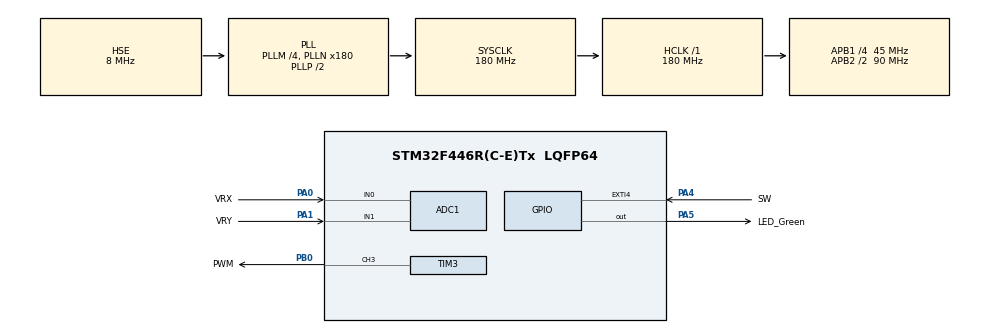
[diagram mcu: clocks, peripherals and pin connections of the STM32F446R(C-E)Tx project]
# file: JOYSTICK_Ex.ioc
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ADC1.Channel-2\#ChannelRegularConversion=ADC_CHANNEL_0
ADC1.Channel-3\#ChannelRegularConversion=ADC_CHANNEL_1
ADC1.ContinuousConvMode=ENABLE
ADC1.DMAContinuousRequests=ENABLE
ADC1.NbrOfConversion=2
ADC1.NbrOfConversionFlag=1
ADC1.Rank-2\#ChannelRegularConversion=1
ADC1.Rank-3\#ChannelRegularConversion=2
ADC1.SamplingTime-2\#ChannelRegularConversion=ADC_SAMPLETIME_84CYCLES
ADC1.SamplingTime-3\#ChannelRegularConversion=ADC_SAMPLETIME_84CYCLES
ADC1.master=1
Dma.ADC1.0.Direction=DMA_PERIPH_TO_MEMORY
Dma.ADC1.0.FIFOMode=DMA_FIFOMODE_DISABLE
Dma.ADC1.0.Instance=DMA2_Stream0
Dma.ADC1.0.MemDataAlignment=DMA_MDATAALIGN_HALFWORD
Dma.ADC1.0.MemInc=DMA_MINC_ENABLE
Dma.ADC1.0.Mode=DMA_CIRCULAR
Dma.ADC1.0.PeriphDataAlignment=DMA_PDATAALIGN_HALFWORD
Dma.ADC1.0.PeriphInc=DMA_PINC_DISABLE
Dma.ADC1.0.Priority=DMA_PRIORITY_LOW
Dma.Request0=ADC1
Mcu.Family=STM32F4
Mcu.Name=STM32F446R(C-E)Tx
Mcu.Package=LQFP64
NVIC.DMA2_Stream0_IRQn=true\:0\:0\:false\:false\:true\:false\:true
NVIC.EXTI4_IRQn=true\:0\:0\:false\:false\:true\:true\:true
NVIC.PriorityGroup=NVIC_PRIORITYGROUP_4
NVIC.TIM3_IRQn=true\:0\:0\:false\:false\:true\:true\:true
PA0-WKUP.GPIO_Label=VRX
PA0-WKUP.Signal=ADCx_IN0
PA1.GPIO_Label=VRY
PA1.Signal=ADCx_IN1
PA4.GPIO_Label=SW
PA4.GPIO_ModeDefaultEXTI=GPIO_MODE_IT_RISING
PA4.GPIO_PuPd=GPIO_PULLDOWN
PA4.Signal=GPXTI4
PA5.GPIO_Label=LED_Green
PA5.Signal=GPIO_Output
PB0.GPIO_Label=PWM
PB0.Signal=S_TIM3_CH3
PH0-OSC_IN.Mode=HSE-External-Oscillator
PH0-OSC_IN.Signal=RCC_OSC_IN
PH1-OSC_OUT.Mode=HSE-External-Oscillator
PH1-OSC_OUT.Signal=RCC_OSC_OUT
ProjectManager.HeapSize=0x200
ProjectManager.StackSize=0x400
ProjectManager.TargetToolchain=STM32CubeIDE
RCC.AHBFreq_Value=180000000
RCC.APB1CLKDivider=RCC_HCLK_DIV4
RCC.APB1Freq_Value=45000000
RCC.APB1TimFreq_Value=90000000
RCC.APB2CLKDivider=RCC_HCLK_DIV2
RCC.APB2Freq_Value=90000000
RCC.APB2TimFreq_Value=180000000
RCC.CortexFreq_Value=180000000
RCC.HCLKFreq_Value=180000000
RCC.HSE_VALUE=8000000
RCC.PLLM=4
RCC.PLLN=180
RCC.PLLSourceVirtual=RCC_PLLSOURCE_HSE
RCC.SYSCLKFreq_VALUE=180000000
RCC.SYSCLKSource=RCC_SYSCLKSOURCE_PLLCLK
RCC.USBFreq_Value=180000000
RCC.VCOOutputFreq_Value=360000000
SH.ADCx_IN0.0=ADC1_IN0,IN0
SH.ADCx_IN1.0=ADC1_IN1,IN1
SH.S_TIM3_CH3.0=TIM3_CH3,PWM Generation3 CH3
TIM3.Channel-PWM\ Generation3\ CH3=TIM_CHANNEL_3
TIM3.Period=10000-1
TIM3.Prescaler=180-1
VP_TIM3_VS_ClockSourceINT.Mode=Internal
board=custom

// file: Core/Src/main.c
/* USER CODE BEGIN Header */
/**
  ******************************************************************************
  * @file           : main.c
  * @brief          : Main program body
  ******************************************************************************
  * @attention
  *
  * <h2><center>&copy; Copyright (c) 2020 STMicroelectronics.
  * All rights reserved.</center></h2>
  *
  * This software component is licensed by ST under BSD 3-Clause license,
  * the "License"; You may not use this file except in compliance with the
  * License. You may obtain a copy of the License at:
  *                        opensource.org/licenses/BSD-3-Clause
  *
  ******************************************************************************
  */
/* USER CODE END Header */

#include "main.h"

ADC_HandleTypeDef hadc1;
DMA_HandleTypeDef hdma_adc1;

TIM_HandleTypeDef htim3;

/* USER CODE BEGIN PV */
uint16_t Joystick_Data[2];
uint32_t Pwm=0;
uint16_t i=450;

/* USER CODE END PV */

void SystemClock_Config(void);
static void MX_GPIO_Init(void);
static void MX_DMA_Init(void);
static void MX_ADC1_Init(void);
static void MX_TIM3_Init(void);

/* USER CODE BEGIN 0 */
uint32_t map(uint32_t data ,uint32_t bound_0,uint32_t bound_1,uint32_t new_bound_0,uint32_t new_bound_1){

	return ((data-bound_0)*(new_bound_1-new_bound_0))/(bound_1-bound_0)+new_bound_0;
}
void HAL_GPIO_EXTI_Callback(uint16_t GPIO_Pin) {
	/*if(EXTI->PR & 1<<4)
	 HAL_GPIO_TogglePin(GPIOA, GPIO_PIN_5);
	 EXTI->PR	|= 1<<4;		//	Clear interrupt flag*/

}

void HAL_ADC_ConvCpltCallback(ADC_HandleTypeDef *hadc) {
	Pwm = map(Joystick_Data[0], 0, 4095, 450, 1310);
}

/* USER CODE END 0 */

int main(void)
{

  /* MCU Configuration--------------------------------------------------------*/

  /* Reset of all peripherals, Initializes the Flash interface and the Systick. */
  HAL_Init();

  /* Configure the system clock */
  SystemClock_Config();

  /* Initialize all configured peripherals */
  MX_GPIO_Init();
  MX_DMA_Init();
  MX_ADC1_Init();
  MX_TIM3_Init();
  /* USER CODE BEGIN 2 */
  HAL_ADC_Start_DMA(&hadc1,(uint32_t*)Joystick_Data,2);
  HAL_TIM_PWM_Start(&htim3, TIM_CHANNEL_3);
  /* USER CODE END 2 */

  /* Infinite loop */
  /* USER CODE BEGIN WHILE */
	while (1) {
		__HAL_TIM_SET_COMPARE(&htim3, TIM_CHANNEL_3, Pwm);
		HAL_Delay(1);

		/*while(i<1310){
			__HAL_TIM_SET_COMPARE(&htim3, TIM_CHANNEL_3, i);
			HAL_Delay(1);
			i++;
		}
		while(i>450){
			__HAL_TIM_SET_COMPARE(&htim3, TIM_CHANNEL_3, i);
						HAL_Delay(1);
						i--;
		}*/

		/* USER CODE END WHILE */

  }
}

void SystemClock_Config(void)
{
  RCC_OscInitTypeDef RCC_OscInitStruct = {0};
  RCC_ClkInitTypeDef RCC_ClkInitStruct = {0};

  /** Configure the main internal regulator output voltage
  */
  __HAL_RCC_PWR_CLK_ENABLE();
  __HAL_PWR_VOLTAGESCALING_CONFIG(PWR_REGULATOR_VOLTAGE_SCALE1);
  /** Initializes the CPU, AHB and APB busses clocks
  */
  RCC_OscInitStruct.OscillatorType = RCC_OSCILLATORTYPE_HSE;
  RCC_OscInitStruct.HSEState = RCC_HSE_ON;
  RCC_OscInitStruct.PLL.PLLState = RCC_PLL_ON;
  RCC_OscInitStruct.PLL.PLLSource = RCC_PLLSOURCE_HSE;
  RCC_OscInitStruct.PLL.PLLM = 4;
  RCC_OscInitStruct.PLL.PLLN = 180;
  RCC_OscInitStruct.PLL.PLLP = RCC_PLLP_DIV2;
  RCC_OscInitStruct.PLL.PLLQ = 2;
  RCC_OscInitStruct.PLL.PLLR = 2;
  if (HAL_RCC_OscConfig(&RCC_OscInitStruct) != HAL_OK)
  {
    Error_Handler();
  }
  /** Activate the Over-Drive mode
  */
  if (HAL_PWREx_EnableOverDrive() != HAL_OK)
  {
    Error_Handler();
  }
  /** Initializes the CPU, AHB and APB busses clocks
  */
  RCC_ClkInitStruct.ClockType = RCC_CLOCKTYPE_HCLK|RCC_CLOCKTYPE_SYSCLK
                              |RCC_CLOCKTYPE_PCLK1|RCC_CLOCKTYPE_PCLK2;
  RCC_ClkInitStruct.SYSCLKSource = RCC_SYSCLKSOURCE_PLLCLK;
  RCC_ClkInitStruct.AHBCLKDivider = RCC_SYSCLK_DIV1;
  RCC_ClkInitStruct.APB1CLKDivider = RCC_HCLK_DIV4;
  RCC_ClkInitStruct.APB2CLKDivider = RCC_HCLK_DIV2;

  if (HAL_RCC_ClockConfig(&RCC_ClkInitStruct, FLASH_LATENCY_5) != HAL_OK)
  {
    Error_Handler();
  }
}

static void MX_ADC1_Init(void)
{

  ADC_ChannelConfTypeDef sConfig = {0};

  /** Configure the global features of the ADC (Clock, Resolution, Data Alignment and number of conversion)
  */
  hadc1.Instance = ADC1;
  hadc1.Init.ClockPrescaler = ADC_CLOCK_SYNC_PCLK_DIV4;
  hadc1.Init.Resolution = ADC_RESOLUTION_12B;
  hadc1.Init.ScanConvMode = ENABLE;
  hadc1.Init.ContinuousConvMode = ENABLE;
  hadc1.Init.DiscontinuousConvMode = DISABLE;
  hadc1.Init.ExternalTrigConvEdge = ADC_EXTERNALTRIGCONVEDGE_NONE;
  hadc1.Init.ExternalTrigConv = ADC_SOFTWARE_START;
  hadc1.Init.DataAlign = ADC_DATAALIGN_RIGHT;
  hadc1.Init.NbrOfConversion = 2;
  hadc1.Init.DMAContinuousRequests = ENABLE;
  hadc1.Init.EOCSelection = ADC_EOC_SINGLE_CONV;
  if (HAL_ADC_Init(&hadc1) != HAL_OK)
  {
    Error_Handler();
  }
  /** Configure for the selected ADC regular channel its corresponding rank in the sequencer and its sample time.
  */
  sConfig.Channel = ADC_CHANNEL_0;
  sConfig.Rank = 1;
  sConfig.SamplingTime = ADC_SAMPLETIME_84CYCLES;
  if (HAL_ADC_ConfigChannel(&hadc1, &sConfig) != HAL_OK)
  {
    Error_Handler();
  }
  /** Configure for the selected ADC regular channel its corresponding rank in the sequencer and its sample time.
  */
  sConfig.Channel = ADC_CHANNEL_1;
  sConfig.Rank = 2;
  if (HAL_ADC_ConfigChannel(&hadc1, &sConfig) != HAL_OK)
  {
    Error_Handler();
  }

}

static void MX_TIM3_Init(void)
{

  TIM_ClockConfigTypeDef sClockSourceConfig = {0};
  TIM_MasterConfigTypeDef sMasterConfig = {0};
  TIM_OC_InitTypeDef sConfigOC = {0};

  htim3.Instance = TIM3;
  htim3.Init.Prescaler = 180-1;
  htim3.Init.CounterMode = TIM_COUNTERMODE_UP;
  htim3.Init.Period = 10000-1;
  htim3.Init.ClockDivision = TIM_CLOCKDIVISION_DIV1;
  htim3.Init.AutoReloadPreload = TIM_AUTORELOAD_PRELOAD_DISABLE;
  if (HAL_TIM_Base_Init(&htim3) != HAL_OK)
  {
    Error_Handler();
  }
  sClockSourceConfig.ClockSource = TIM_CLOCKSOURCE_INTERNAL;
  if (HAL_TIM_ConfigClockSource(&htim3, &sClockSourceConfig) != HAL_OK)
  {
    Error_Handler();
  }
  if (HAL_TIM_PWM_Init(&htim3) != HAL_OK)
  {
    Error_Handler();
  }
  sMasterConfig.MasterOutputTrigger = TIM_TRGO_RESET;
  sMasterConfig.MasterSlaveMode = TIM_MASTERSLAVEMODE_DISABLE;
  if (HAL_TIMEx_MasterConfigSynchronization(&htim3, &sMasterConfig) != HAL_OK)
  {
    Error_Handler();
  }
  sConfigOC.OCMode = TIM_OCMODE_PWM1;
  sConfigOC.Pulse = 0;
  sConfigOC.OCPolarity = TIM_OCPOLARITY_HIGH;
  sConfigOC.OCFastMode = TIM_OCFAST_DISABLE;
  if (HAL_TIM_PWM_ConfigChannel(&htim3, &sConfigOC, TIM_CHANNEL_3) != HAL_OK)
  {
    Error_Handler();
  }
  HAL_TIM_MspPostInit(&htim3);

}

static void MX_DMA_Init(void)
{

  /* DMA controller clock enable */
  __HAL_RCC_DMA2_CLK_ENABLE();

  /* DMA interrupt init */
  /* DMA2_Stream0_IRQn interrupt configuration */
  HAL_NVIC_SetPriority(DMA2_Stream0_IRQn, 0, 0);
  HAL_NVIC_EnableIRQ(DMA2_Stream0_IRQn);

}

static void MX_GPIO_Init(void)
{
  GPIO_InitTypeDef GPIO_InitStruct = {0};

  /* GPIO Ports Clock Enable */
  __HAL_RCC_GPIOH_CLK_ENABLE();
  __HAL_RCC_GPIOA_CLK_ENABLE();
  __HAL_RCC_GPIOB_CLK_ENABLE();

  /*Configure GPIO pin Output Level */
  HAL_GPIO_WritePin(LED_Green_GPIO_Port, LED_Green_Pin, GPIO_PIN_RESET);

  /*Configure GPIO pin : SW_Pin */
  GPIO_InitStruct.Pin = SW_Pin;
  GPIO_InitStruct.Mode = GPIO_MODE_IT_RISING;
  GPIO_InitStruct.Pull = GPIO_PULLDOWN;
  HAL_GPIO_Init(SW_GPIO_Port, &GPIO_InitStruct);

  /*Configure GPIO pin : LED_Green_Pin */
  GPIO_InitStruct.Pin = LED_Green_Pin;
  GPIO_InitStruct.Mode = GPIO_MODE_OUTPUT_PP;
  GPIO_InitStruct.Pull = GPIO_NOPULL;
  GPIO_InitStruct.Speed = GPIO_SPEED_FREQ_LOW;
  HAL_GPIO_Init(LED_Green_GPIO_Port, &GPIO_InitStruct);

  /* EXTI interrupt init*/
  HAL_NVIC_SetPriority(EXTI4_IRQn, 0, 0);
  HAL_NVIC_EnableIRQ(EXTI4_IRQn);

}

void Error_Handler(void)
{
}

/************************ (C) COPYRIGHT STMicroelectronics *****END OF FILE****/
